# wsoc_mcu_secure register map
Vendor: Texas Instruments
Peripheral module from a debugger description file (folder CC35X1E).
Registers are 32-bit, access per field, reset 0x0 unless marked. A register's access mark holds for its fields unless they carry their own. Offsets are as the file gives them; lines under a group give offsets from that group; [hi:lo] are bit positions; {n}, {i} and the like mark numbered series; 'fields as' and 'values as' point back to an identical list; <NAME> marks a mode.

## wsoc_mcu_secure
0x00 device_id ro reset 0xCC33CC33
  [15:0] DEVICE_ID
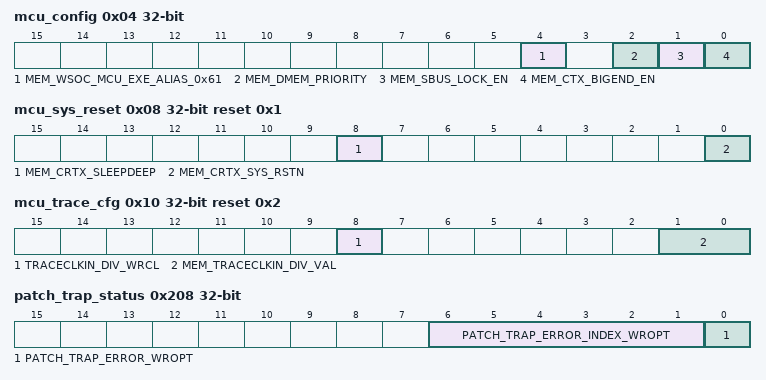
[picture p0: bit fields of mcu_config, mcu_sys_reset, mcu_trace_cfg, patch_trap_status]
0x04 mcu_config reset not defined
  [4] MEM_WSOC_MCU_EXE_ALIAS_0x61 rw — When Set every acess to 0x61xx_xxxx wil be aimed back to NWPW 0x45xx_xxxx This give execution ability to MEM that are located inside nwpw (XN region)
  [2] MEM_DMEM_PRIORITY rw — 0 - OCPS has high priority over SBUS 1 - SBUS has high priority over OCPS
  [1] MEM_SBUS_LOCK_EN rw
  [0] MEM_CTX_BIGEND_EN rw
0x08 mcu_sys_reset reset 0x1
  [8] MEM_CRTX_SLEEPDEEP rw — Force SLEEPDEEP indication toward WUCAAONSVT: 0 - Cortex SLEEPDEEP is not forced. 1 - Cortex SLEEPDEEP is set to 1 toward WUCAAONSVT
  [0] MEM_CRTX_SYS_RSTN rw — -- New for O3 --- Cortex released from reset after wake up - Jtag can connect - SDIO set this bit to force reset so it can load CRAM safely. Force reset by SDIO in order to safely Load CRAM. 0 - Cortex set into reset by sdio 1 - Cortex SYS reset release (Default) --------------------- -- OLD pre O3 --- <placed here just for comparison> Force reset on wakeup till S/W releases it. 0 - Cortex is in reset (default) 1 - Cortex SYS reset release ---------------------
0x10 mcu_trace_cfg reset 0x2 — Configuration register for CortexM3-TPIU (TRACE ports i/o unit)
  [8] TRACECLKIN_DIV_WRCL wo — Set this register to load 'mem_traceclk_div_val'
  [1:0] MEM_TRACECLKIN_DIV_VAL rw — Configure TRACE-CLOCK divider value, for (TPIU - input clock) [1] - Divide by 2 - 'tpiu_trace_clk_in' = 40MHz [2] - Divide by 4 - 'tpiu_trace_clk_in' = 20MHz (Default) [0,3] - are not supported (do not use) AFTER setting this value - set 'traceclk_div_wrcl' to active this value
0x14 mcu_sw_timestamp — Configuration register for CortexM3 SW Time-Stamp
  [15:0] MEM_MCU_SW_TIMESTAMP rw — SW Time-Stamp for debug (as for Energy Trace).
0x100 patch_trap_addresses — Patch Trap Addresses Configuration.
  [19:0] MEM_PATCH_TRAP_ADDRESSES_1FC_WRMEMP rw — NOTE: two LSBs are ignored at write and considered to be 2'b00 at read, the two LSBs will always be 2'b00 Support up 64 pathced entry Address configuration for each of the 0 -31 optional addresses - consecutive address from 0x100 - 0x017C for 0-31 - MX1 & MX2 Address configuration for each of the 32-63 optional addresses - consecutive address from 0x180 - 0x01FC for 32-63 - MX1 only
0x200 patch_trap_addr_en_0 rw — Configuration Patch Trap
  [31:0] MEM_PATCH_TRAP_ADDRESS_ENABLE_0 — 32 Enable bits - one for each patch-trap configurable addresses [0-31]
0x204 patch_trap_addr_en_1 rw — Configuration Patch Trap
  [31:0] MEM_PATCH_TRAP_ADDRESS_ENABLE_1 — 32 Enable bits - one for each patch-trap configurable addresses [32-63] This field exist only when Number of patches above 32 - e.g. MX1 has 64 patches
0x208 patch_trap_status — Patch Trap Status RO register
  [6:1] PATCH_TRAP_ERROR_INDEX_WROPT rw — Index status which of the configurable addresses is patch-trapped MX1 - [0-63] MX2 - [0-31] (Clear-By-SW (WR))
  [0] PATCH_TRAP_ERROR_WROPT rw — Sticky bit to tell if any patch trap is detected (Clear-By-SW (WR) )
0x210 patch_trap_cfg — Config for Patch-Trap HW
  [0] MEM_PATCH_TRAP_CFG0 rw
0x22C addr_error_status ro
  [31:0] ADDR_ERROR_STATUS — 32-bit address during the error the cause should be read at ADDR_ERROR_CAUSE register cleared on write to ADDR_ERROR_CAUSE sticky - catch the address of first error, until ADDR_ERROR_CAUSE is cleared
0x230 addr_error_cause
  [3:0] ADDR_ERROR_CAUSE_WROPT rw — the cause of address-error kept in ADDR_ERROR_STATUS 0000 - clear value 0001 - ahb write error 0010 - address watch - read transaction 0011 - address watch - write transaction 0100 - bit-access error - add overflow 0101 - bit-access error - sub underflow 0110 - bit-access error - read-sresp error 0111 - bit-access error - mcmd error 1000 - stack overflow detect - read transaction 1001 - stack overflow detect - write transaction
0x234 addr_error_code_status ro
  [31:0] ADDR_ERROR_CODE_STATUS — 32-bit code-address during the error the cause should be read at ADDR_ERROR_CAUSE register cleared on write to ADDR_ERROR_CAUSE sticky - catch the address of first error, until ADDR_ERROR_CAUSE is cleared
0x240 stack_addr_start rw
  [31:0] MEM_STACK_ADDR_START — first valid address of stack
0x244 stack_addr_end rw
  [31:0] MEM_STACK_ADDR_END — last valid address of stack
0x248 stack_void_size reset not defined
  [7:0] MEM_STACK_VOID_SIZE_KB rw — size in KByte of void area of stack_overflow_detect. set VOID_SIZE to 0 will disable the stack_overflow_detect two void area exist: void1 = below STACK_START : error if (STACK_START-VOID_SIZE =< address < STACK_START) void2 = above STACK_END : error if (STACK_END < address =< STACK_END+VOID_SIZE) any RD/WR to void area will cause SBUS-AHB bus-fault
0x24C stack_max_depth_fpga_only
  [19:0] MEM_STACK_MAX_DEPTH_WROPT rw — FPGA_ONLY register max-hold of stack-depth in bytes clear-on-write 0
0x250 mcu_spare rw reset not defined
  [31:0] MEM_MCU_SPARE
0x254 mcu_ocla_sw_signaling_set wo reset not defined
  [31:0] MEM_OCLA_SW_SIGNALING_SET_WRCL — write '1' to one or more of these bits to set corresponding bit/bits
0x258 mcu_ocla_sw_signaling_clr wo reset not defined
  [31:0] MEM_OCLA_SW_SIGNALING_CLR_WRCL — write '1' to one or more of these bits to clear corresponding bit/bits
0x25C mcu_ocla_sw_signaling_tgl wo reset not defined
  [31:0] MEM_OCLA_SW_SIGNALING_TGL_WRCL — write '1' to one or more of these bits to toggle corresponding bit/bits
0x260 mcu_ocla_sw_signaling_rw rw reset not defined
  [31:0] MEM_OCLA_SW_SIGNALING_WROPT — read or write to one or more of these bits to set or clear corresponding bit/bits
